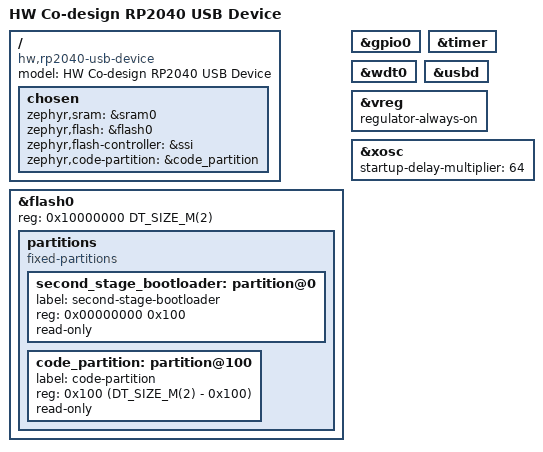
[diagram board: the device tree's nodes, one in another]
/dts-v1/;
#include <raspberrypi/rpi_pico/rp2040.dtsi>
#include <mem.h>

/ {
	model = "HW Co-design RP2040 USB Device";
	compatible = "hw,rp2040-usb-device";

	chosen {
		zephyr,sram = &sram0;
		zephyr,flash = &flash0;
		zephyr,flash-controller = &ssi;
		zephyr,code-partition = &code_partition;
	};
};

&flash0 {
	reg = <0x10000000 DT_SIZE_M(2)>;

	partitions {
		compatible = "fixed-partitions";
		#address-cells = <1>;
		#size-cells = <1>;

		second_stage_bootloader: partition@0 {
			label = "second-stage-bootloader";
			reg = <0x00000000 0x100>;
			read-only;
		};

		code_partition: partition@100 {
			label = "code-partition";
			reg = <0x100 (DT_SIZE_M(2) - 0x100)>;
			read-only;
		};
	};
};

&gpio0 {
	status = "okay";
};

&timer {
	status = "okay";
};

&wdt0 {
	status = "okay";
};

zephyr_udc0: &usbd {
	status = "okay";
};

&vreg {
	regulator-always-on;
};

&xosc {
	startup-delay-multiplier = <64>;
};
